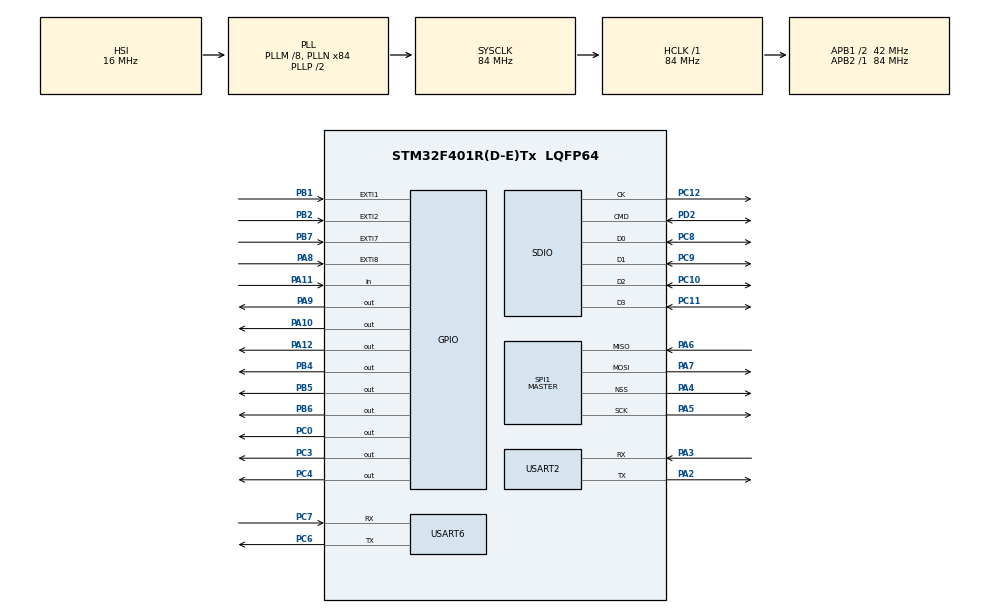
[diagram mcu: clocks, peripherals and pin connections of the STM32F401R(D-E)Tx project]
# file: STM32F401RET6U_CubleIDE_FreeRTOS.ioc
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Dma.Request0=USART2_RX
Dma.Request1=USART2_TX
Dma.Request2=SDIO_RX
Dma.Request3=SDIO_TX
Dma.SDIO_RX.2.Direction=DMA_PERIPH_TO_MEMORY
Dma.SDIO_RX.2.FIFOMode=DMA_FIFOMODE_ENABLE
Dma.SDIO_RX.2.FIFOThreshold=DMA_FIFO_THRESHOLD_FULL
Dma.SDIO_RX.2.Instance=DMA2_Stream3
Dma.SDIO_RX.2.MemBurst=DMA_MBURST_INC4
Dma.SDIO_RX.2.MemDataAlignment=DMA_MDATAALIGN_WORD
Dma.SDIO_RX.2.MemInc=DMA_MINC_ENABLE
Dma.SDIO_RX.2.Mode=DMA_PFCTRL
Dma.SDIO_RX.2.PeriphBurst=DMA_PBURST_INC4
Dma.SDIO_RX.2.PeriphDataAlignment=DMA_PDATAALIGN_WORD
Dma.SDIO_RX.2.PeriphInc=DMA_PINC_DISABLE
Dma.SDIO_RX.2.Priority=DMA_PRIORITY_LOW
Dma.SDIO_TX.3.Direction=DMA_MEMORY_TO_PERIPH
Dma.SDIO_TX.3.FIFOMode=DMA_FIFOMODE_ENABLE
Dma.SDIO_TX.3.FIFOThreshold=DMA_FIFO_THRESHOLD_FULL
Dma.SDIO_TX.3.Instance=DMA2_Stream6
Dma.SDIO_TX.3.MemBurst=DMA_MBURST_INC4
Dma.SDIO_TX.3.MemDataAlignment=DMA_MDATAALIGN_WORD
Dma.SDIO_TX.3.MemInc=DMA_MINC_ENABLE
Dma.SDIO_TX.3.Mode=DMA_PFCTRL
Dma.SDIO_TX.3.PeriphBurst=DMA_PBURST_INC4
Dma.SDIO_TX.3.PeriphDataAlignment=DMA_PDATAALIGN_WORD
Dma.SDIO_TX.3.PeriphInc=DMA_PINC_DISABLE
Dma.SDIO_TX.3.Priority=DMA_PRIORITY_LOW
Dma.USART2_RX.0.Direction=DMA_PERIPH_TO_MEMORY
Dma.USART2_RX.0.FIFOMode=DMA_FIFOMODE_DISABLE
Dma.USART2_RX.0.Instance=DMA1_Stream5
Dma.USART2_RX.0.MemDataAlignment=DMA_MDATAALIGN_BYTE
Dma.USART2_RX.0.MemInc=DMA_MINC_ENABLE
Dma.USART2_RX.0.Mode=DMA_CIRCULAR
Dma.USART2_RX.0.PeriphDataAlignment=DMA_PDATAALIGN_BYTE
Dma.USART2_RX.0.PeriphInc=DMA_PINC_DISABLE
Dma.USART2_RX.0.Priority=DMA_PRIORITY_MEDIUM
Dma.USART2_TX.1.Direction=DMA_MEMORY_TO_PERIPH
Dma.USART2_TX.1.FIFOMode=DMA_FIFOMODE_DISABLE
Dma.USART2_TX.1.Instance=DMA1_Stream6
Dma.USART2_TX.1.MemDataAlignment=DMA_MDATAALIGN_BYTE
Dma.USART2_TX.1.MemInc=DMA_MINC_ENABLE
Dma.USART2_TX.1.Mode=DMA_NORMAL
Dma.USART2_TX.1.PeriphDataAlignment=DMA_PDATAALIGN_BYTE
Dma.USART2_TX.1.PeriphInc=DMA_PINC_DISABLE
Dma.USART2_TX.1.Priority=DMA_PRIORITY_MEDIUM
FATFS._CODE_PAGE=1
FATFS._FS_NORTC=1
FATFS._FS_REENTRANT=0
FATFS._NORTC_MDAY=1
FATFS._NORTC_YEAR=2024
FATFS._USE_FASTSEEK=0
FATFS._USE_MKFS=0
FATFS._USE_STRFUNC=0
FREERTOS.Tasks01=defaultTask,24,1600,StartDefaultTask,Default,NULL,Dynamic,NULL,NULL
FREERTOS.configGENERATE_RUN_TIME_STATS=1
FREERTOS.configMINIMAL_STACK_SIZE=128
FREERTOS.configTOTAL_HEAP_SIZE=51200
FREERTOS.configUSE_STATS_FORMATTING_FUNCTIONS=1
Mcu.Family=STM32F4
Mcu.Name=STM32F401R(D-E)Tx
Mcu.Package=LQFP64
NVIC.DMA1_Stream5_IRQn=true\:5\:0\:false\:false\:true\:true\:false\:true\:true
NVIC.DMA1_Stream6_IRQn=true\:5\:0\:false\:false\:true\:true\:false\:true\:true
NVIC.DMA2_Stream3_IRQn=true\:6\:0\:true\:false\:true\:true\:false\:true\:true
NVIC.DMA2_Stream6_IRQn=true\:5\:0\:false\:false\:true\:true\:false\:true\:true
NVIC.EXTI1_IRQn=true\:5\:0\:false\:false\:true\:true\:true\:true\:true
NVIC.EXTI2_IRQn=true\:5\:0\:false\:false\:true\:true\:true\:true\:true
NVIC.EXTI9_5_IRQn=true\:5\:0\:false\:false\:true\:true\:true\:true\:true
NVIC.PriorityGroup=NVIC_PRIORITYGROUP_4
NVIC.SDIO_IRQn=true\:6\:0\:true\:false\:true\:true\:true\:true\:true
NVIC.USART2_IRQn=true\:5\:0\:false\:false\:true\:true\:true\:true\:true
NVIC.USART6_IRQn=true\:5\:0\:false\:false\:true\:true\:true\:true\:true
PA10.Signal=GPIO_Output
PA11.Signal=GPIO_Input
PA12.Signal=GPIO_Output
PA13.Mode=Serial_Wire
PA13.Signal=SYS_JTMS-SWDIO
PA14.Mode=Serial_Wire
PA14.Signal=SYS_JTCK-SWCLK
PA2.Mode=Asynchronous
PA2.Signal=USART2_TX
PA3.Mode=Asynchronous
PA3.Signal=USART2_RX
PA4.Mode=NSS_Signal_Hard_Output
PA4.Signal=SPI1_NSS
PA5.Mode=Full_Duplex_Master
PA5.Signal=SPI1_SCK
PA6.Mode=Full_Duplex_Master
PA6.Signal=SPI1_MISO
PA7.Mode=Full_Duplex_Master
PA7.Signal=SPI1_MOSI
PA8.GPIO_ModeDefaultEXTI=GPIO_MODE_IT_RISING_FALLING
PA8.GPIO_PuPd=GPIO_PULLUP
PA8.Signal=GPXTI8
PA9.Signal=GPIO_Output
PB1.GPIO_ModeDefaultEXTI=GPIO_MODE_IT_RISING_FALLING
PB1.GPIO_PuPd=GPIO_PULLUP
PB1.Signal=GPXTI1
PB2.GPIO_ModeDefaultEXTI=GPIO_MODE_IT_RISING_FALLING
PB2.GPIO_PuPd=GPIO_PULLUP
PB2.Signal=GPXTI2
PB3.Signal=SYS_JTDO-SWO
PB4.Signal=GPIO_Output
PB5.Signal=GPIO_Output
PB6.Signal=GPIO_Output
PB7.GPIO_ModeDefaultEXTI=GPIO_MODE_IT_RISING_FALLING
PB7.GPIO_PuPd=GPIO_PULLUP
PB7.Signal=GPXTI7
PC0.Signal=GPIO_Output
PC10.Mode=SD_4_bits_Wide_bus
PC10.Signal=SDIO_D2
PC11.Mode=SD_4_bits_Wide_bus
PC11.Signal=SDIO_D3
PC12.Mode=SD_4_bits_Wide_bus
PC12.Signal=SDIO_CK
PC14-OSC32_IN.Mode=LSE-External-Oscillator
PC14-OSC32_IN.Signal=RCC_OSC32_IN
PC15-OSC32_OUT.Mode=LSE-External-Oscillator
PC15-OSC32_OUT.Signal=RCC_OSC32_OUT
PC3.Signal=GPIO_Output
PC4.Signal=GPIO_Output
PC6.Mode=Asynchronous
PC6.Signal=USART6_TX
PC7.Mode=Asynchronous
PC7.Signal=USART6_RX
PC8.Mode=SD_4_bits_Wide_bus
PC8.Signal=SDIO_D0
PC9.Mode=SD_4_bits_Wide_bus
PC9.Signal=SDIO_D1
PD2.Mode=SD_4_bits_Wide_bus
PD2.Signal=SDIO_CMD
PH0\ -\ OSC_IN.Mode=HSE-External-Oscillator
PH0\ -\ OSC_IN.Signal=RCC_OSC_IN
PH1\ -\ OSC_OUT.Mode=HSE-External-Oscillator
PH1\ -\ OSC_OUT.Signal=RCC_OSC_OUT
ProjectManager.HeapSize=0x400
ProjectManager.StackSize=0x800
ProjectManager.TargetToolchain=STM32CubeIDE
RCC.48MHZClocksFreq_Value=42000000
RCC.AHBFreq_Value=84000000
RCC.APB1CLKDivider=RCC_HCLK_DIV2
RCC.APB1Freq_Value=42000000
RCC.APB1TimFreq_Value=84000000
RCC.APB2Freq_Value=84000000
RCC.APB2TimFreq_Value=84000000
RCC.CortexFreq_Value=84000000
RCC.HCLKFreq_Value=84000000
RCC.HSE_VALUE=25000000
RCC.HSI_VALUE=16000000
RCC.PLLM=8
RCC.PLLN=84
RCC.SYSCLKFreq_VALUE=84000000
RCC.SYSCLKSource=RCC_SYSCLKSOURCE_PLLCLK
RCC.VCOOutputFreq_Value=168000000
SDIO.ClockDiv=6
SPI1.Direction=SPI_DIRECTION_2LINES
SPI1.Mode=SPI_MODE_MASTER
SPI1.VirtualNSS=VM_NSSHARD
SPI1.VirtualType=VM_MASTER
USART2.VirtualMode=VM_ASYNC
USART6.VirtualMode=VM_ASYNC
VP_FATFS_VS_SDIO.Mode=SDIO
VP_FREERTOS_VS_CMSIS_V2.Mode=CMSIS_V2
board=custom

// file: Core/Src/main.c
/* USER CODE BEGIN Header */
/**
  ******************************************************************************
  * @file           : main.c
  * @brief          : Main program body
  ******************************************************************************
  * @attention
  *
  * Copyright (c) 2023 STMicroelectronics.
  * All rights reserved.
  *
  * This software is licensed under terms that can be found in the LICENSE file
  * in the root directory of this software component.
  * If no LICENSE file comes with this software, it is provided AS-IS.
  *
  ******************************************************************************
  */
/* USER CODE END Header */
#include "main.h"
#include "cmsis_os.h"
#include "fatfs.h"

 SD_HandleTypeDef hsd;
DMA_HandleTypeDef hdma_sdio_rx;
DMA_HandleTypeDef hdma_sdio_tx;

SPI_HandleTypeDef hspi1;

UART_HandleTypeDef huart2;
UART_HandleTypeDef huart6;
DMA_HandleTypeDef hdma_usart2_rx;
DMA_HandleTypeDef hdma_usart2_tx;

/* Definitions for defaultTask */
osThreadId_t defaultTaskHandle;
const osThreadAttr_t defaultTask_attributes = {
  .name = "defaultTask",
  .stack_size = 1600 * 4,
  .priority = (osPriority_t) osPriorityNormal,
};

void SystemClock_Config(void);
static void MX_GPIO_Init(void);
static void MX_DMA_Init(void);
static void MX_USART2_UART_Init(void);
static void MX_USART6_UART_Init(void);
static void MX_SPI1_Init(void);
static void MX_SDIO_SD_Init(void);
void StartDefaultTask(void *argument);

int main(void)
{

  /* MCU Configuration--------------------------------------------------------*/

  /* Reset of all peripherals, Initializes the Flash interface and the Systick. */

	HAL_Init();

  /* Configure the system clock */
  SystemClock_Config();

  /* Initialize all configured peripherals */
  MX_GPIO_Init();
  MX_DMA_Init();
  MX_USART2_UART_Init();
  MX_USART6_UART_Init();
  MX_SPI1_Init();
  MX_SDIO_SD_Init();
  MX_FATFS_Init();

  /* Init scheduler */
  osKernelInitialize();

  /* Create the thread(s) */
  /* creation of defaultTask */
  defaultTaskHandle = osThreadNew(StartDefaultTask, NULL, &defaultTask_attributes);

  /* Start scheduler */
  osKernelStart();

  /* We should never get here as control is now taken by the scheduler */
  /* Infinite loop */
  while (1)
  {

  }
}

void SystemClock_Config(void)
{
  RCC_OscInitTypeDef RCC_OscInitStruct = {0};
  RCC_ClkInitTypeDef RCC_ClkInitStruct = {0};

  /** Configure the main internal regulator output voltage
  */
  __HAL_RCC_PWR_CLK_ENABLE();
  __HAL_PWR_VOLTAGESCALING_CONFIG(PWR_REGULATOR_VOLTAGE_SCALE2);

  /** Initializes the RCC Oscillators according to the specified parameters
  * in the RCC_OscInitTypeDef structure.
  */
  RCC_OscInitStruct.OscillatorType = RCC_OSCILLATORTYPE_HSI;
  RCC_OscInitStruct.HSIState = RCC_HSI_ON;
  RCC_OscInitStruct.HSICalibrationValue = RCC_HSICALIBRATION_DEFAULT;
  RCC_OscInitStruct.PLL.PLLState = RCC_PLL_ON;
  RCC_OscInitStruct.PLL.PLLSource = RCC_PLLSOURCE_HSI;
  RCC_OscInitStruct.PLL.PLLM = 8;
  RCC_OscInitStruct.PLL.PLLN = 84;
  RCC_OscInitStruct.PLL.PLLP = RCC_PLLP_DIV2;
  RCC_OscInitStruct.PLL.PLLQ = 4;
  if (HAL_RCC_OscConfig(&RCC_OscInitStruct) != HAL_OK)
  {
    Error_Handler();
  }

  /** Initializes the CPU, AHB and APB buses clocks
  */
  RCC_ClkInitStruct.ClockType = RCC_CLOCKTYPE_HCLK|RCC_CLOCKTYPE_SYSCLK
                              |RCC_CLOCKTYPE_PCLK1|RCC_CLOCKTYPE_PCLK2;
  RCC_ClkInitStruct.SYSCLKSource = RCC_SYSCLKSOURCE_PLLCLK;
  RCC_ClkInitStruct.AHBCLKDivider = RCC_SYSCLK_DIV1;
  RCC_ClkInitStruct.APB1CLKDivider = RCC_HCLK_DIV2;
  RCC_ClkInitStruct.APB2CLKDivider = RCC_HCLK_DIV1;

  if (HAL_RCC_ClockConfig(&RCC_ClkInitStruct, FLASH_LATENCY_2) != HAL_OK)
  {
    Error_Handler();
  }
}

static void MX_SDIO_SD_Init(void)
{

  hsd.Instance = SDIO;
  hsd.Init.ClockEdge = SDIO_CLOCK_EDGE_RISING;
  hsd.Init.ClockBypass = SDIO_CLOCK_BYPASS_DISABLE;
  hsd.Init.ClockPowerSave = SDIO_CLOCK_POWER_SAVE_DISABLE;
  hsd.Init.BusWide = SDIO_BUS_WIDE_1B;
  hsd.Init.HardwareFlowControl = SDIO_HARDWARE_FLOW_CONTROL_DISABLE;
  hsd.Init.ClockDiv = 6;

}

static void MX_SPI1_Init(void)
{

  /* SPI1 parameter configuration*/
  hspi1.Instance = SPI1;
  hspi1.Init.Mode = SPI_MODE_MASTER;
  hspi1.Init.Direction = SPI_DIRECTION_2LINES;
  hspi1.Init.DataSize = SPI_DATASIZE_8BIT;
  hspi1.Init.CLKPolarity = SPI_POLARITY_LOW;
  hspi1.Init.CLKPhase = SPI_PHASE_1EDGE;
  hspi1.Init.NSS = SPI_NSS_HARD_OUTPUT;
  hspi1.Init.BaudRatePrescaler = SPI_BAUDRATEPRESCALER_2;
  hspi1.Init.FirstBit = SPI_FIRSTBIT_MSB;
  hspi1.Init.TIMode = SPI_TIMODE_DISABLE;
  hspi1.Init.CRCCalculation = SPI_CRCCALCULATION_DISABLE;
  hspi1.Init.CRCPolynomial = 10;
  if (HAL_SPI_Init(&hspi1) != HAL_OK)
  {
    Error_Handler();
  }

}

static void MX_USART2_UART_Init(void)
{

  huart2.Instance = USART2;
  huart2.Init.BaudRate = 115200;
  huart2.Init.WordLength = UART_WORDLENGTH_8B;
  huart2.Init.StopBits = UART_STOPBITS_1;
  huart2.Init.Parity = UART_PARITY_NONE;
  huart2.Init.Mode = UART_MODE_TX_RX;
  huart2.Init.HwFlowCtl = UART_HWCONTROL_NONE;
  huart2.Init.OverSampling = UART_OVERSAMPLING_16;
  if (HAL_UART_Init(&huart2) != HAL_OK)
  {
    Error_Handler();
  }

}

static void MX_USART6_UART_Init(void)
{

  huart6.Instance = USART6;
  huart6.Init.BaudRate = 115200;
  huart6.Init.WordLength = UART_WORDLENGTH_8B;
  huart6.Init.StopBits = UART_STOPBITS_1;
  huart6.Init.Parity = UART_PARITY_NONE;
  huart6.Init.Mode = UART_MODE_TX_RX;
  huart6.Init.HwFlowCtl = UART_HWCONTROL_NONE;
  huart6.Init.OverSampling = UART_OVERSAMPLING_16;
  if (HAL_UART_Init(&huart6) != HAL_OK)
  {
    Error_Handler();
  }

}

static void MX_DMA_Init(void)
{

  /* DMA controller clock enable */
  __HAL_RCC_DMA1_CLK_ENABLE();
  __HAL_RCC_DMA2_CLK_ENABLE();

  /* DMA interrupt init */
  /* DMA1_Stream5_IRQn interrupt configuration */
  HAL_NVIC_SetPriority(DMA1_Stream5_IRQn, 5, 0);
  HAL_NVIC_EnableIRQ(DMA1_Stream5_IRQn);
  /* DMA1_Stream6_IRQn interrupt configuration */
  HAL_NVIC_SetPriority(DMA1_Stream6_IRQn, 5, 0);
  HAL_NVIC_EnableIRQ(DMA1_Stream6_IRQn);
  /* DMA2_Stream3_IRQn interrupt configuration */
  HAL_NVIC_SetPriority(DMA2_Stream3_IRQn, 6, 0);
  HAL_NVIC_EnableIRQ(DMA2_Stream3_IRQn);
  /* DMA2_Stream6_IRQn interrupt configuration */
  HAL_NVIC_SetPriority(DMA2_Stream6_IRQn, 5, 0);
  HAL_NVIC_EnableIRQ(DMA2_Stream6_IRQn);

}

static void MX_GPIO_Init(void)
{
  GPIO_InitTypeDef GPIO_InitStruct = {0};

  /* GPIO Ports Clock Enable */
  __HAL_RCC_GPIOC_CLK_ENABLE();
  __HAL_RCC_GPIOH_CLK_ENABLE();
  __HAL_RCC_GPIOA_CLK_ENABLE();
  __HAL_RCC_GPIOB_CLK_ENABLE();
  __HAL_RCC_GPIOD_CLK_ENABLE();

  /*Configure GPIO pin Output Level */
  HAL_GPIO_WritePin(GPIOC, GPIO_PIN_0|GPIO_PIN_3|GPIO_PIN_4, GPIO_PIN_RESET);

  /*Configure GPIO pin Output Level */
  HAL_GPIO_WritePin(GPIOA, GPIO_PIN_9|GPIO_PIN_10|GPIO_PIN_12, GPIO_PIN_RESET);

  /*Configure GPIO pin Output Level */
  HAL_GPIO_WritePin(GPIOB, GPIO_PIN_4|GPIO_PIN_5|GPIO_PIN_6, GPIO_PIN_RESET);

  /*Configure GPIO pins : PC0 PC3 PC4 */
  GPIO_InitStruct.Pin = GPIO_PIN_0|GPIO_PIN_3|GPIO_PIN_4;
  GPIO_InitStruct.Mode = GPIO_MODE_OUTPUT_PP;
  GPIO_InitStruct.Pull = GPIO_NOPULL;
  GPIO_InitStruct.Speed = GPIO_SPEED_FREQ_LOW;
  HAL_GPIO_Init(GPIOC, &GPIO_InitStruct);

  /*Configure GPIO pins : PB1 PB2 PB7 */
  GPIO_InitStruct.Pin = GPIO_PIN_1|GPIO_PIN_2|GPIO_PIN_7;
  GPIO_InitStruct.Mode = GPIO_MODE_IT_RISING_FALLING;
  GPIO_InitStruct.Pull = GPIO_PULLUP;
  HAL_GPIO_Init(GPIOB, &GPIO_InitStruct);

  /*Configure GPIO pin : PA8 */
  GPIO_InitStruct.Pin = GPIO_PIN_8;
  GPIO_InitStruct.Mode = GPIO_MODE_IT_RISING_FALLING;
  GPIO_InitStruct.Pull = GPIO_PULLUP;
  HAL_GPIO_Init(GPIOA, &GPIO_InitStruct);

  /*Configure GPIO pins : PA9 PA10 PA12 */
  GPIO_InitStruct.Pin = GPIO_PIN_9|GPIO_PIN_10|GPIO_PIN_12;
  GPIO_InitStruct.Mode = GPIO_MODE_OUTPUT_PP;
  GPIO_InitStruct.Pull = GPIO_NOPULL;
  GPIO_InitStruct.Speed = GPIO_SPEED_FREQ_LOW;
  HAL_GPIO_Init(GPIOA, &GPIO_InitStruct);

  /*Configure GPIO pin : PA11 */
  GPIO_InitStruct.Pin = GPIO_PIN_11;
  GPIO_InitStruct.Mode = GPIO_MODE_INPUT;
  GPIO_InitStruct.Pull = GPIO_NOPULL;
  HAL_GPIO_Init(GPIOA, &GPIO_InitStruct);

  /*Configure GPIO pins : PB4 PB5 PB6 */
  GPIO_InitStruct.Pin = GPIO_PIN_4|GPIO_PIN_5|GPIO_PIN_6;
  GPIO_InitStruct.Mode = GPIO_MODE_OUTPUT_PP;
  GPIO_InitStruct.Pull = GPIO_NOPULL;
  GPIO_InitStruct.Speed = GPIO_SPEED_FREQ_LOW;
  HAL_GPIO_Init(GPIOB, &GPIO_InitStruct);

  /* EXTI interrupt init*/
  HAL_NVIC_SetPriority(EXTI1_IRQn, 5, 0);
  HAL_NVIC_EnableIRQ(EXTI1_IRQn);

  HAL_NVIC_SetPriority(EXTI2_IRQn, 5, 0);
  HAL_NVIC_EnableIRQ(EXTI2_IRQn);

  HAL_NVIC_SetPriority(EXTI9_5_IRQn, 5, 0);
  HAL_NVIC_EnableIRQ(EXTI9_5_IRQn);

}

void StartDefaultTask(void *argument)
{
  /* USER CODE BEGIN 5 */
  extern void hardware_init(void);
  hardware_init();
  user_main(argument);
  /* USER CODE END 5 */
}

void Error_Handler(void)
{
  __disable_irq();
  while (1)
  {
  }
}
